# calc5_target_db register map
Vendor: Texas Instruments
Address unit: 16 bits
Registers are 32-bit, read-write, reset 0x0 unless marked. A register's access mark holds for its fields unless they carry their own. Offsets are as the file gives them; [hi:lo] are bit positions; {n}, {i} and the like mark numbered series; 'fields as' and 'values as' point back to an identical list.

## DSS (part 3 of 4) — ipxact12_to_ccs_generated
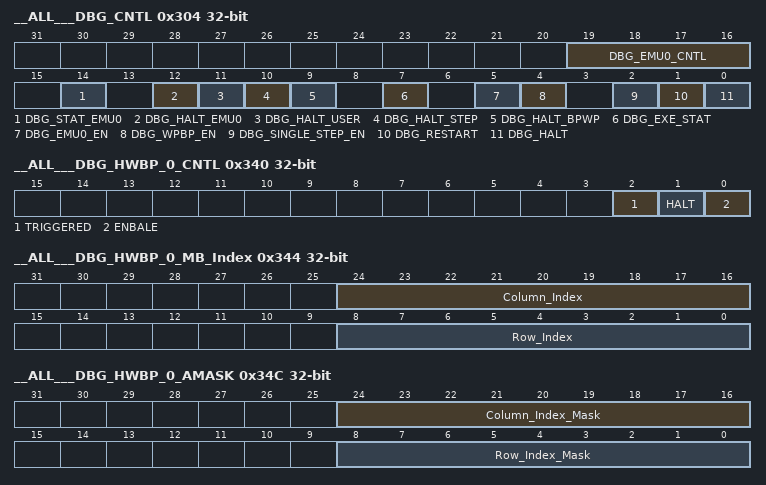
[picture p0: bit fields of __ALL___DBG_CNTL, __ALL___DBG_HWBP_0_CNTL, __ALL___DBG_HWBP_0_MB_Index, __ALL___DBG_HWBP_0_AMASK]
0x304 __ALL___DBG_CNTL access per field — Debug Control register is used by debug software to control all of the basic debug functions.
  [19:16] DBG_EMU0_CNTL ro — EMU0 output control. The cross trigger output control. This values in this field determine the behavior of the outputs generated on EMU0. NOTE: The effect of setting ‘1’ is ignored if the HWA Core is currently in HALTED state until the HWA core exits and re-enters HALTED state. 0 : No output. Input only 1 : Pulse on halt. If this bit is set when halted then no effect until the HWA re-enters halted state. 2 : Pulse when any HWBP triggers 3 : Pulse when any HWWP triggers 4 : Drive pin high 5 : Drive pin low 6-15 : Reserved
  [14] DBG_STAT_EMU0 ro — Statues of EMU0 input. This bit indicates the current value of the EMU0 input
  [12] DBG_HALT_EMU0 ro — Execution halted due to trigger in on EMU0 input • Set to ‘1’ when halt due to EMU0 input completes • Set to ‘0’ when execution resumes
  [11] DBG_HALT_USER ro — Execution halted due to register update of DBG_HALT • Set to ‘1’ when halt due to DBG_HALT update completes • Set to ‘0’ when execution resumes
  [10] DBG_HALT_STEP ro — Execution halted due to single step completion • Set to ‘1’ when the single step completes • Set to ‘0’ when execution resumes
  [9] DBG_HALT_BPWP ro — Execution halted due to trigger from HWBP or WP. • Set to ‘1’ halt due to breakpoint or watchpoint completes • Set to ‘0’ when execution resumes
  [7] DBG_EXE_STAT ro — The execution status of the module • Set to ‘1’ when halted due to debug event • Set to ‘0’ when execution resumes
  [5] DBG_EMU0_EN rw — EMU0 input trigger enable • Writing ‘1’ enables halting on the falling edge of the EMU0 input • Writing ‘0’ disables halts via EMU0 input
  [4] DBG_WPBP_EN rw — This bit enables the halts on watchpoint or hardware breakpoint trigger events. • Writing ‘1’ enables halting on any hardware breakpoint or watchpoint trigger  Each breakpoint or watchpoint resource also has a local enable • Writing ‘0’ disables halts via hardware breakpoints or watchpoints
  [2] DBG_SINGLE_STEP_EN rw — Single Step Execution enable When this bit is set, the accelerator core shall be halted upon execution of a single instruction. This is after the accelerator core has left the halted state by clearing the DBG_HALT control bit. • Writing ‘1’ enables halting when the next instruction following exit from halted state is executed. • Writing ‘0’ disables halts via single step. NOTE: 1. When the accelerator core enters its natural execution state, it may or may not execute an instruction and re-enter HALTED state.
  [1] DBG_RESTART rw — Debug Restart Status bit • Reading ‘1’ means HWA Core exited halted state (at least temporarily). • Reading ‘0’ means HWA Core did not exit halted state. • Writing ‘1’ shall clear the bit if set. There is no restriction on when it can be cleared. • Writing ‘0’ shall have no effect.
  [0] DBG_HALT rw — Global debug run control The bit will be read as being set upon entry to HALTED state due to halted state being entered because of SWBP, HWBP, HWWP, EMU0 / 1 trigger or manual halt requested through this control. • Writing ‘1’ when read ‘0’ shall cause a halt on the next possible halt boundary. • Writing ‘0’ when read ‘1’ returns the system to the natural execution state. • Reading ‘1’ means that the halted state has been reached. • Reading ‘0’ means that the target is in its natural execution state. NOTE: 1. The natural execution state means the FSM state entered prior to last entry into Halted state. 2. This would be the last application requested FSM state unless the DBG_SYS_EXE_REQ control was used to change it.
0x340 __ALL___DBG_HWBP_0_CNTL access per field — Hardware Brakepoint-0 Control (at MB-Index)
  [2] TRIGGERED rw — This bit is Set to "1" when HWBP located at the MB_Index in DBG_HWBP_n_MB_Index is executed Set to ‘1’ when executing the MB index = DBG_HWBP_n_MB_Index Cleared to ‘0’ by writing ‘1’ to this bit
  [1] HALT rw — This bit configures the module to generate halt when triggered [1] : enables a processor halt when triggered. The DBG_CNTL:DBG_HALT_BPWP must also be set for the halt to occur [0] : disables halt upon trigger
  [0] ENBALE rw — This is the local enable for the hardware breakpoint module Writing ‘1’ to this bit enables the module to generate an instruction address match trigger Writing ‘0’ to this bit disables the module
0x344 __ALL___DBG_HWBP_0_MB_Index access per field — Hardware Brakepoint-0 : At MB-Index
  [24:16] Column_Index rw — Column index of the MB. After processing that MB HWA will halt
  [8:0] Row_Index rw — Row index of the MB. After processing that MB HWA will halt
0x34C __ALL___DBG_HWBP_0_AMASK access per field — Hardware Brakepoint-0 : mask At MB-Index
  [24:16] Column_Index_Mask rw — Mask for the column index of DBG_HWBP_n_MB_INDEX
  [8:0] Row_Index_Mask rw — Mask for the row index of DBG_HWBP_n_MB_INDEX
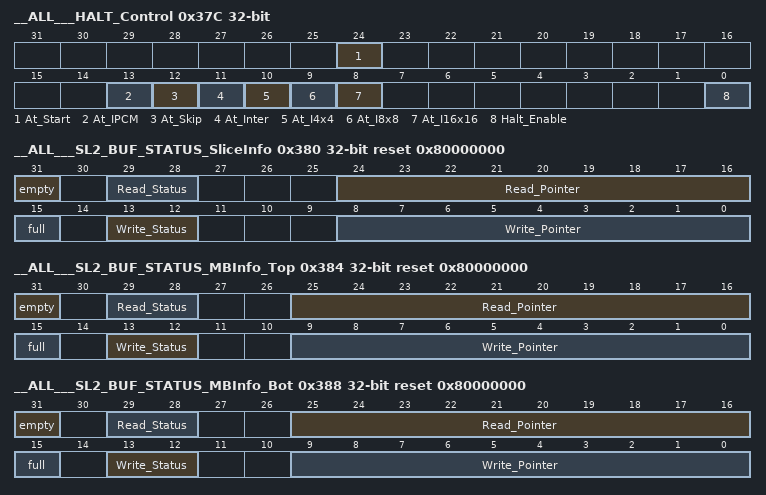
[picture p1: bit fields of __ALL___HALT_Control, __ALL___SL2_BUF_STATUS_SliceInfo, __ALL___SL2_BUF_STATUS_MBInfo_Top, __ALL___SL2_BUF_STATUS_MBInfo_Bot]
0x37C __ALL___HALT_Control access per field — Halt Control of CALC5
  [24] At_Start rw — [1] : Halt when all BC are ready.. (Juster befor start of Computation) [0] : Halt just before releasing BC (Just after computation is done)
  [13] At_IPCM rw — Halt when "mb_type=2" in MB-Info
  [12] At_Skip rw — Halt when MB is skip in MB-Info in Decoder
  [11] At_Inter rw — Halt when "mb_type=3" in MB-Info
  [10] At_I4x4 rw — Halt when "mb_type=0 and tr_8x8=0" in MB-Info
  [9] At_I8x8 rw — Halt when "mb_type=0 and tr_8x8=1" in MB-Info
  [8] At_I16x16 rw — Halt when "mb_type=1" in MB-Info
  [0] Halt_Enable rw — Enable Halt of CALC at different Stage
0x380 __ALL___SL2_BUF_STATUS_SliceInfo ro reset 0x80000000
  [31] empty — buffer empty status ‘1’ -> buffer is empty ‘0’ -> buffer is not empty
  [29:28] Read_Status — Indicates the BC status on the read side BC NOT READY = 00 (rd_core_busy=0 & rd_bc_ready=0) BC READY = 01 (rd_core_busy=0 & rd_bc_ready=1) BC BUSY = 1x (rd_core_busy=1)
  [24:16] Read_Pointer — Current Read pointer value which is going to be read or being read. Read pointer will always be less than equal to ‘Actual buffer depth – 1’
  [15] full — buffer full status ‘1’ -> buffer is full ‘0’ -> buffer is not full
  [13:12] Write_Status — Indicates the BC status on the write side BC NOT READY = 00 (wr_core_busy=0 & wr_bc_ready=0) BC READY = 01 (wr_core_busy=0 & wr_bc_ready=1) BC BUSY = 1x (wr_core_busy=1)
  [8:0] Write_Pointer — Current Write pointer value which is going to be written or which is being written. Write pointer will always be less than equal to ‘Actual buffer depth – 1’
0x384 __ALL___SL2_BUF_STATUS_MBInfo_Top ro reset 0x80000000
  [31] empty — buffer empty status ‘1’ -> buffer is empty ‘0’ -> buffer is not empty
  [29:28] Read_Status — Indicates the BC status on the read side BC NOT READY = 00 (rd_core_busy=0 & rd_bc_ready=0) BC READY = 01 (rd_core_busy=0 & rd_bc_ready=1) BC BUSY = 1x (rd_core_busy=1)
  [25:16] Read_Pointer — Current Read pointer value which is going to be read or being read. Read pointer will always be less than equal to ‘Actual buffer depth – 1’
  [15] full — buffer full status ‘1’ -> buffer is full ‘0’ -> buffer is not full
  [13:12] Write_Status — Indicates the BC status on the write side BC NOT READY = 00 (wr_core_busy=0 & wr_bc_ready=0) BC READY = 01 (wr_core_busy=0 & wr_bc_ready=1) BC BUSY = 1x (wr_core_busy=1)
  [9:0] Write_Pointer — Current Write pointer value which is going to be written or which is being written. Write pointer will always be less than equal to ‘Actual buffer depth – 1’
0x388 __ALL___SL2_BUF_STATUS_MBInfo_Bot ro reset 0x80000000
  fields as __ALL___SL2_BUF_STATUS_MBInfo_Top
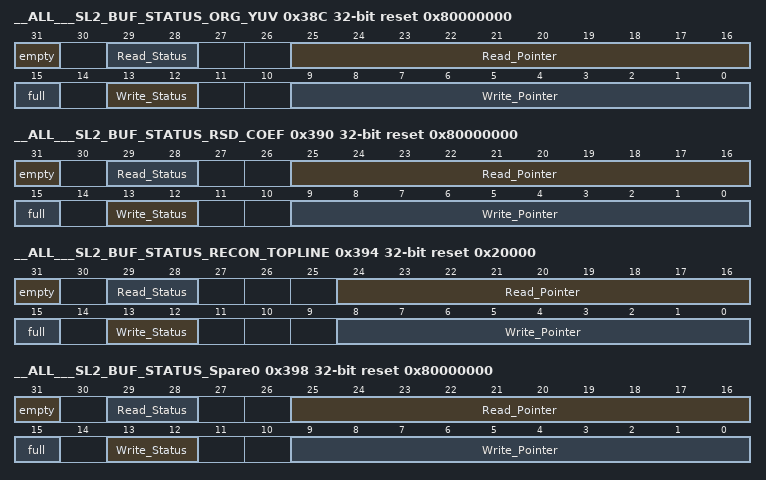
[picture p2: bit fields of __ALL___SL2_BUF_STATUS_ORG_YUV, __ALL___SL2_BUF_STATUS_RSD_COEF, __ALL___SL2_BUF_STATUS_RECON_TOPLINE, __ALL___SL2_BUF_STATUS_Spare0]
0x38C __ALL___SL2_BUF_STATUS_ORG_YUV ro reset 0x80000000
  fields as __ALL___SL2_BUF_STATUS_MBInfo_Top
0x390 __ALL___SL2_BUF_STATUS_RSD_COEF ro reset 0x80000000
  fields as __ALL___SL2_BUF_STATUS_MBInfo_Top
0x394 __ALL___SL2_BUF_STATUS_RECON_TOPLINE ro reset 0x20000
  fields as __ALL___SL2_BUF_STATUS_SliceInfo
0x398 __ALL___SL2_BUF_STATUS_Spare0 ro reset 0x80000000
  fields as __ALL___SL2_BUF_STATUS_MBInfo_Top
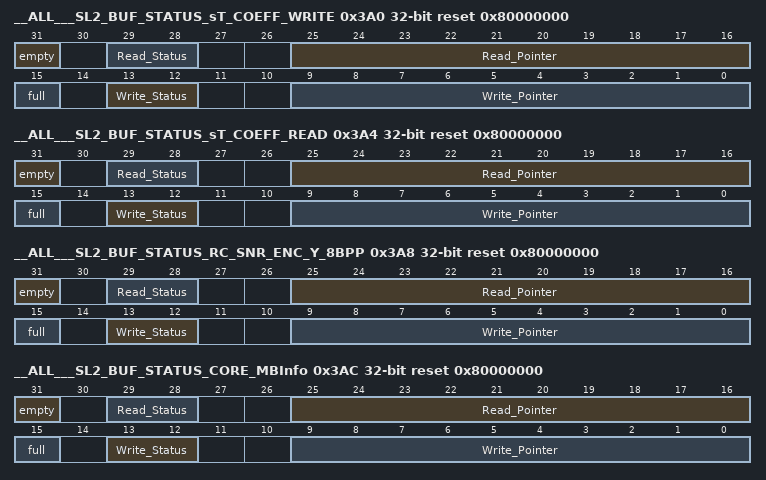
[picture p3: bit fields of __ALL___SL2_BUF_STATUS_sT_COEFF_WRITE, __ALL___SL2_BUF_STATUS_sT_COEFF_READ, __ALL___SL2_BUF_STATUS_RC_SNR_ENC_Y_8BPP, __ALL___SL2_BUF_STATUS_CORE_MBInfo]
0x3A0 __ALL___SL2_BUF_STATUS_sT_COEFF_WRITE ro reset 0x80000000 — stcoeff write SL2BC status
  fields as __ALL___SL2_BUF_STATUS_MBInfo_Top
0x3A4 __ALL___SL2_BUF_STATUS_sT_COEFF_READ ro reset 0x80000000 — stcoeff read SL2BC status
  fields as __ALL___SL2_BUF_STATUS_MBInfo_Top
0x3A8 __ALL___SL2_BUF_STATUS_RC_SNR_ENC_Y_8BPP ro reset 0x80000000 — rc 8bpp luma data write SL2BC status
  fields as __ALL___SL2_BUF_STATUS_MBInfo_Top
0x3AC __ALL___SL2_BUF_STATUS_CORE_MBInfo ro reset 0x80000000 — SL2BC between calc core and drm status
  fields as __ALL___SL2_BUF_STATUS_MBInfo_Top
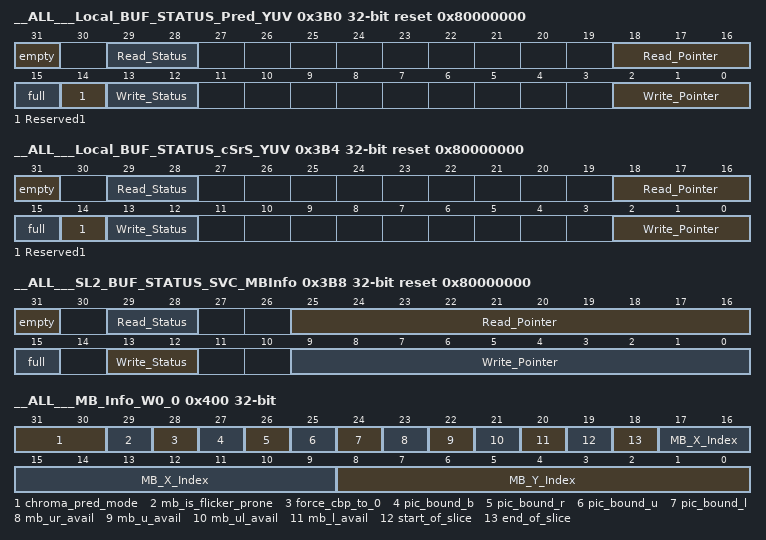
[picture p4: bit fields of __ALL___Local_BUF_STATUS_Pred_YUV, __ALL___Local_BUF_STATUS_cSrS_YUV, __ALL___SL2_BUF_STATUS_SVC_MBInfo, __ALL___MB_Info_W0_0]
0x3B0 __ALL___Local_BUF_STATUS_Pred_YUV ro reset 0x80000000 — Status of Pred-Buffer (LBC)
  [31] empty — buffer empty status ‘1’ -> buffer is empty ‘0’ -> buffer is not empty
  [29:28] Read_Status — Indicates the BC status on the read side BC NOT READY = 00 (rd_core_busy=0 & rd_bc_ready=0) BC READY = 01 (rd_core_busy=0 & rd_bc_ready=1) BC BUSY = 1x (rd_core_busy=1)
  [18:16] Read_Pointer — Current Read pointer value which is going to be read or being read. Read pointer will always be less than equal to ‘Actual buffer depth – 1’
  [15] full — buffer full status ‘1’ -> buffer is full ‘0’ -> buffer is not full
  [14] Reserved1 — Indicates the BC status on the write side BC NOT READY = 00 (wr_core_busy=0 & wr_bc_ready=0) BC READY = 01 (wr_core_busy=0 & wr_bc_ready=1) BC BUSY = 1x (wr_core_busy=1)
  [13:12] Write_Status
  [2:0] Write_Pointer — Current Write pointer value which is going to be written or which is being written. Write pointer will always be less than equal to ‘Actual buffer depth – 1’
0x3B4 __ALL___Local_BUF_STATUS_cSrS_YUV ro reset 0x80000000 — Status of cS/rS-Buffer (LBC) used in SVC
  fields as __ALL___Local_BUF_STATUS_Pred_YUV
0x3B8 __ALL___SL2_BUF_STATUS_SVC_MBInfo ro reset 0x80000000 — SL2BC between me and calc drm status
  fields as __ALL___SL2_BUF_STATUS_MBInfo_Top
0x3C0 __ALL___W_BUF_STATUS_RECON_LEFTLINE ro reset 0x3
  [1:0] ul_refpix_ptr — Upper-Left Reference-Pixel pointer in W-buf
0x400 __ALL___MB_Info_W0_0 ro
  [31:30] chroma_pred_mode — In Intra -> contain Chrom Pred Mode. In Inter -> LSB contain SKIP status
  [29] mb_is_flicker_prone — In Encode valid for I-Frame Only [0] : Normal Function. [1] : Use MC output as Original.
  [28] force_cbp_to_0 — In Encoder [0] -> Normal Operation [1] -> DIFF will be Forced to Zero (Org-Pred = 0) (In Inter it is same as SKIP-MB) In Decoder [0] : Normal MB [1] : MB with Error
  [27] pic_bound_b
  [26] pic_bound_r
  [25] pic_bound_u
  [24] pic_bound_l
  [23] mb_ur_avail
  [22] mb_u_avail
  [21] mb_ul_avail
  [20] mb_l_avail
  [19] start_of_slice
  [18] end_of_slice
  [17:9] MB_X_Index — Column_Index of MB
  [8:0] MB_Y_Index — Row_Index of MB
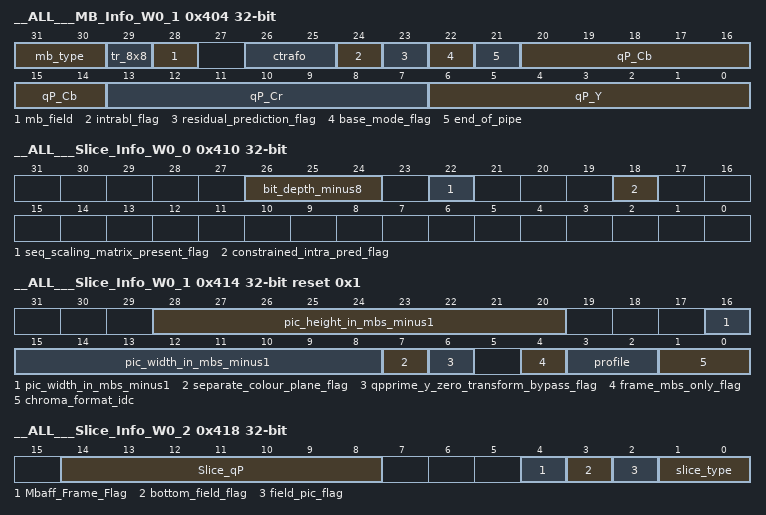
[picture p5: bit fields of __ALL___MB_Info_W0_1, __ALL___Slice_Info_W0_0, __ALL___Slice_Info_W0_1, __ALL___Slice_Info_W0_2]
0x404 __ALL___MB_Info_W0_1 ro
  [31:30] mb_type — [0] : Intra_4x4 or Intra_8x8 [1] : Intra_16x16 [2] : I_PCM [3] : Inter
  [29] tr_8x8 — valid when "mb_type = 0" and "mb_type = 3" [0] : 4x4 transform [1] : 8x8 transform
  [28] mb_field — Valid for MBAFF [0] : Frame MB-pair [1] : Field MB-Pair
  [26:25] ctrafo — SVC field
  [24] intrabl_flag — SVC field
  [23] residual_prediction_flag — SVC field
  [22] base_mode_flag — SVC field
  [21] end_of_pipe
  [20:14] qP_Cb — Cb qP (0-to-39)
  [13:7] qP_Cr — Cr qP (0-to-39)
  [6:0] qP_Y — Luma qP (0-to-51)
0x408 __ALL___MB_Info_W0_2 ro — Intra_mode
  [31:0] Y_pred_mode
0x40C __ALL___MB_Info_W0_3 ro — Intra_Modes
  [31:0] Y_pred_mode
0x410 __ALL___Slice_Info_W0_0 ro
  [26:24] bit_depth_minus8 — specifies the bit depth of the samples of the luma and Chroma (Valid only when design support more than 8-bit pixle)
  [22] seq_scaling_matrix_present_flag — equal to 1 specifies that the WeightScale matrix is present. seq_scaling_matrix_present_flag equal to 0 specifies that these flags are not present and the sequence-level scaling list specified by Flat_4x4_16 (Constant 16 value). This flag can be present only in High-Profile
  [18] constrained_intra_pred_flag
0x414 __ALL___Slice_Info_W0_1 ro reset 0x1
  [28:20] pic_height_in_mbs_minus1
  [16:8] pic_width_in_mbs_minus1
  [7] separate_colour_plane_flag — Valid only for 4:4:4
  [6] qpprime_y_zero_transform_bypass_flag — equal to 1 specifies that, when QP'Y is equal to 0, a transform bypass operation for the transform coefficient decoding process and picture construction process prior to deblocking filter process is applied (Valied only in High 4:4:4 profile)
  [4] frame_mbs_only_flag — equal to 0 specifies that coded pictures of the coded video sequence may either be coded fields or coded frames.
  [3:2] profile — 0: Baseline Profile, 1: Main Profile, 2: High Profile, 3: Reserved.
  [1:0] chroma_format_idc — 0 : 4:0:0, 1 : 4:2:0, 2 : 4:2:2, 3 : 4:4:4
0x418 __ALL___Slice_Info_W0_2 ro
  [14:8] Slice_qP — qP of a slice.
  [4] Mbaff_Frame_Flag — MbaffFrameFlag = ( mb_adaptive_frame_field_flag && !field_pic_flag ). mb_adaptive_frame_field_flag equal to 0 specifies no switching between frame and field macroblock within a picture.
  [3] bottom_field_flag — equal to 1 specifies that the slice is part of a coded bottom field. bottom_field_flag equal to 0 specifies that the picture is a coded top field. When this syntax element is not present for the current slice, it shall be inferred to be equal to 0
  [2] field_pic_flag — equal to 1 specifies that the slice is a slice of a coded field. field_pic_flag equal to 0 specifies that the slice is a slice of a coded frame
  [1:0] slice_type — 0 : I-Slice, 1 : P-Slice, 2 : B-Slie, 3 : Reserved
0x41C __ALL___Slice_Info_W0_3 ro
0x420 __ALL___Core_Status ro
  [0] CORE_Status — CALC5 core status Write [x] : Ignored Read [0] : waiting for Buffer if "CALC5_EN=1" else Idle Read [1] : Computation in progress
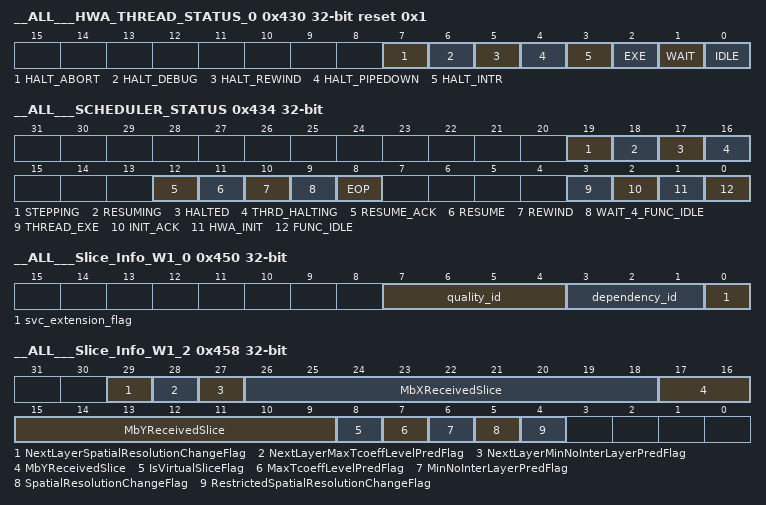
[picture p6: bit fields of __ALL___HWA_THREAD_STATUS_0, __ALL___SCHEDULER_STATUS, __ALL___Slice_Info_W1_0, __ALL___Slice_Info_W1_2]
0x430 __ALL___HWA_THREAD_STATUS_0 ro reset 0x1 — Thread Status
  [7] HALT_ABORT — Halted. abort request is pending
  [6] HALT_DEBUG — Halted. debug request is pending or ongoing.
  [5] HALT_REWIND — Halted because of rewind
  [4] HALT_PIPEDOWN — Thread piped down
  [3] HALT_INTR — Halted because of interrupt request
  [2] EXE — Execution state
  [1] WAIT — Waiting for the Tstart_req
  [0] IDLE — Thread FSM is in IDLE state
0x434 __ALL___SCHEDULER_STATUS ro — Indicates HWA Status
  [19] STEPPING — Stepping the HWA
  [18] RESUMING — Resuming the HWA
  [17] HALTED — HWA halted
  [16] THRD_HALTING — Halting the HWA CORE threads in progress
  [12] RESUME_ACK — = po_resumepipe_ack
  [11] RESUME — HWA is resuming the MB processing. NOTE: po_ rewind_attn = REWIND || RESUME after rewind
  [10] REWIND — HWA is ready to be rewinded
  [9] WAIT_4_FUNC_IDLE — HWA has completed the EOP processing
  [8] EOP — HWA is doing the EOP processing
  [3] THREAD_EXE — HWA Threads are in EXE state
  [2] INIT_ACK — = po_hwa_init_ack
  [1] HWA_INIT — HWA is autoloading/initializing
  [0] FUNC_IDLE — Idle state
{0x440+4i} __ALL___MB_Info_W1_{i} ro (i=0..2)
0x44C __ALL___MB_Info_W1_3 ro
  [22:16] dqId — SVC field
0x450 __ALL___Slice_Info_W1_0 ro
  [7:4] quality_id — Quality/MGS layer id.
  [3:1] dependency_id — Spatial/CGS layer Id.
  [0] svc_extension_flag — svc_extension_flag indicates whether a nal_unit_header_svc_extension( ) or nal_unit_header_mvc_extension( ) is in in the syntax structure. Must be 1 for SVC.
0x454 __ALL___Slice_Info_W1_1 ro
0x458 __ALL___Slice_Info_W1_2 ro
  [29] NextLayerSpatialResolutionChangeFlag — 0: Next layer has same resolution as this layer. 1: Next layer has a different resolution. This flag determines which all inter layer prediction signals to send out from this layer.
  [28] NextLayerMaxTcoeffLevelPredFlag — Is tcoeff_level_prediction_flag equal to 1 for atleast one slice in the next layer. Determines whether transform data (sTCoeff) or quantized levels (tCoeffLevel) will be sent out from this layer to SDRAM. 0: sTCoeff 1: tCoeffLevel. Must be 0 for encoder.
  [27] NextLayerMinNoInterLayerPredFlag — Is no_inter_layer_prediction_flag equal to 0 for atleast one slice for the next layer. Indicates whether inter layer prediction is used by atleast one slice
  [26:18] MbXReceivedSlice — mbXReceivedSlice can be different from mb_x if this is a virtual slice, (i.e. if virtualSliceFlag is 1). Must be 0 in encoder.
  [17:9] MbYReceivedSlice — mbYReceivedSlice can be different from mb_y if this is a virtual slice (i.e. if virtualSliceFlag is 1). Must be 0 in encoder.
  [8] IsVirtualSliceFlag — Is this a slice that was discarded (intentionally) from an SNR enhancement layer (or unintentionally from spatial layer?) If this is 1, slice_skip_flag also must be set and the decoder will decode as though this is a skip slice.
  [7] MaxTcoeffLevelPredFlag — Is tcoeff_level_prediction_flag equal to 1 for atleast one slice in this layer. Must be 0 for encoder.
  [6] MinNoInterLayerPredFlag — Is no_inter_layer_prediction_flag equal to 0 for atleast one slice for this layer. This indicates inter layer prediction is used by atleast one slice in this layer.
  [5] SpatialResolutionChangeFlag — Flag indicating if this is a spatial enhancement layer
  [4] RestrictedSpatialResolutionChangeFlag — Flag indicating if this is 1:1 or 1:2 scalability with restrictions.
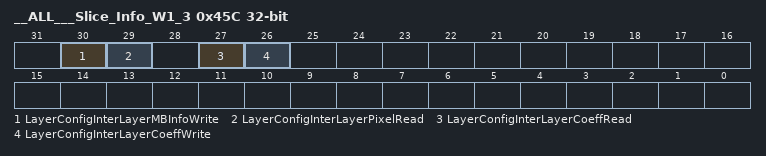
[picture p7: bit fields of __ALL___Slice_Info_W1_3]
0x45C __ALL___Slice_Info_W1_3 ro
  [30] LayerConfigInterLayerMBInfoWrite — Controls CALC vDMA trigger for storing MBInfo to SDRAM.
  [29] LayerConfigInterLayerPixelRead — Controls Pixels scaler vDMA trigger for fetching rS/cS from SDRAM. Also CALC read trigger of rS/cS from SL2 can be avoided if this flag is 0.
  [27] LayerConfigInterLayerCoeffRead — Controls CALC vDMA trigger for fetching sTcoeff/tCoeffLevel from SDRAM
  [26] LayerConfigInterLayerCoeffWrite — Controls CALC vDMA trigger for storing sTcoeff/tCoeffLevel to SDRAM
0x1000 mem__0_one_word
  [31:0] mem_word
0x1004 mem__1_one_word
  [31:0] mem_word
0x1008 mem__2_one_word
  [31:0] mem_word
0x100C mem__3_one_word
  [31:0] mem_word
0x1010 mem__4_one_word
  [31:0] mem_word
0x1014 mem__5_one_word
  [31:0] mem_word
0x1018 mem__6_one_word
  [31:0] mem_word
0x101C mem__7_one_word
  [31:0] mem_word
0x1020 mem__8_one_word
  [31:0] mem_word
0x1024 mem__9_one_word
  [31:0] mem_word
0x1028 mem__10_one_word
  [31:0] mem_word
0x102C mem__11_one_word
  [31:0] mem_word
0x1030 mem__12_one_word
  [31:0] mem_word
0x1034 mem__13_one_word
  [31:0] mem_word
0x1038 mem__14_one_word
  [31:0] mem_word
0x103C mem__15_one_word
  [31:0] mem_word
0x1040 mem__16_one_word
  [31:0] mem_word
0x1044 mem__17_one_word
  [31:0] mem_word
0x1048 mem__18_one_word
  [31:0] mem_word
0x104C mem__19_one_word
  [31:0] mem_word
0x1050 mem__20_one_word
  [31:0] mem_word
0x1054 mem__21_one_word
  [31:0] mem_word
0x1058 mem__22_one_word
  [31:0] mem_word
0x105C mem__23_one_word
  [31:0] mem_word
0x1060 mem__24_one_word
  [31:0] mem_word
0x1064 mem__25_one_word
  [31:0] mem_word
0x1068 mem__26_one_word
  [31:0] mem_word
0x106C mem__27_one_word
  [31:0] mem_word
0x1070 mem__28_one_word
  [31:0] mem_word
0x1074 mem__29_one_word
  [31:0] mem_word
0x1078 mem__30_one_word
  [31:0] mem_word
0x107C mem__31_one_word
  [31:0] mem_word
0x1080 mem__32_one_word
  [31:0] mem_word
0x1084 mem__33_one_word
  [31:0] mem_word
0x1088 mem__34_one_word
  [31:0] mem_word
0x108C mem__35_one_word
  [31:0] mem_word
0x1090 mem__36_one_word
  [31:0] mem_word
0x1094 mem__37_one_word
  [31:0] mem_word
0x1098 mem__38_one_word
  [31:0] mem_word
0x109C mem__39_one_word
  [31:0] mem_word
0x10A0 mem__40_one_word
  [31:0] mem_word
0x10A4 mem__41_one_word
  [31:0] mem_word
0x10A8 mem__42_one_word
  [31:0] mem_word
0x10AC mem__43_one_word
  [31:0] mem_word
0x10B0 mem__44_one_word
  [31:0] mem_word
0x10B4 mem__45_one_word
  [31:0] mem_word
0x10B8 mem__46_one_word
  [31:0] mem_word
0x10BC mem__47_one_word
  [31:0] mem_word
0x10C0 mem__48_one_word
  [31:0] mem_word
0x10C4 mem__49_one_word
  [31:0] mem_word
0x10C8 mem__50_one_word
  [31:0] mem_word
0x10CC mem__51_one_word
  [31:0] mem_word
0x10D0 mem__52_one_word
  [31:0] mem_word
0x10D4 mem__53_one_word
  [31:0] mem_word
0x10D8 mem__54_one_word
  [31:0] mem_word
0x10DC mem__55_one_word
  [31:0] mem_word
0x10E0 mem__56_one_word
  [31:0] mem_word
0x10E4 mem__57_one_word
  [31:0] mem_word
0x10E8 mem__58_one_word
  [31:0] mem_word
0x10EC mem__59_one_word
  [31:0] mem_word
0x10F0 mem__60_one_word
  [31:0] mem_word
0x10F4 mem__61_one_word
  [31:0] mem_word
0x10F8 mem__62_one_word
  [31:0] mem_word
{0x1000+4i} mem__{i}_one_word (i=63..511)
  [31:0] mem_word
0x3000 mem__0_one_word
  [31:0] mem_word
0x3004 mem__1_one_word
  [31:0] mem_word
0x3008 mem__2_one_word
  [31:0] mem_word
0x300C mem__3_one_word
  [31:0] mem_word
0x3010 mem__4_one_word
  [31:0] mem_word
0x3014 mem__5_one_word
  [31:0] mem_word
0x3018 mem__6_one_word
  [31:0] mem_word
0x301C mem__7_one_word
  [31:0] mem_word
0x3020 mem__8_one_word
  [31:0] mem_word
0x3024 mem__9_one_word
  [31:0] mem_word
0x3028 mem__10_one_word
  [31:0] mem_word
0x302C mem__11_one_word
  [31:0] mem_word
0x3030 mem__12_one_word
  [31:0] mem_word
0x3034 mem__13_one_word
  [31:0] mem_word
0x3038 mem__14_one_word
  [31:0] mem_word
0x303C mem__15_one_word
  [31:0] mem_word
0x3040 mem__16_one_word
  [31:0] mem_word
0x3044 mem__17_one_word
  [31:0] mem_word
0x3048 mem__18_one_word
  [31:0] mem_word
0x304C mem__19_one_word
  [31:0] mem_word
0x3050 mem__20_one_word
  [31:0] mem_word
0x3054 mem__21_one_word
  [31:0] mem_word
0x3058 mem__22_one_word
  [31:0] mem_word
0x305C mem__23_one_word
  [31:0] mem_word
0x3060 mem__24_one_word
  [31:0] mem_word
0x3064 mem__25_one_word
  [31:0] mem_word
0x3068 mem__26_one_word
  [31:0] mem_word
0x306C mem__27_one_word
  [31:0] mem_word
0x3070 mem__28_one_word
  [31:0] mem_word
0x3074 mem__29_one_word
  [31:0] mem_word
0x3078 mem__30_one_word
  [31:0] mem_word
0x307C mem__31_one_word
  [31:0] mem_word
0x3080 mem__32_one_word
  [31:0] mem_word
0x3084 mem__33_one_word
  [31:0] mem_word
0x3088 mem__34_one_word
  [31:0] mem_word
0x308C mem__35_one_word
  [31:0] mem_word
0x3090 mem__36_one_word
  [31:0] mem_word
0x3094 mem__37_one_word
  [31:0] mem_word
0x3098 mem__38_one_word
  [31:0] mem_word
0x309C mem__39_one_word
  [31:0] mem_word
0x30A0 mem__40_one_word
  [31:0] mem_word
0x30A4 mem__41_one_word
  [31:0] mem_word
0x30A8 mem__42_one_word
  [31:0] mem_word
0x30AC mem__43_one_word
  [31:0] mem_word
0x30B0 mem__44_one_word
  [31:0] mem_word
0x30B4 mem__45_one_word
  [31:0] mem_word
0x30B8 mem__46_one_word
  [31:0] mem_word
0x30BC mem__47_one_word
  [31:0] mem_word
0x30C0 mem__48_one_word
  [31:0] mem_word
0x30C4 mem__49_one_word
  [31:0] mem_word
0x30C8 mem__50_one_word
  [31:0] mem_word
0x30CC mem__51_one_word
  [31:0] mem_word
0x30D0 mem__52_one_word
  [31:0] mem_word
0x30D4 mem__53_one_word
  [31:0] mem_word
0x30D8 mem__54_one_word
  [31:0] mem_word
0x30DC mem__55_one_word
  [31:0] mem_word
0x30E0 mem__56_one_word
  [31:0] mem_word
0x30E4 mem__57_one_word
  [31:0] mem_word
0x30E8 mem__58_one_word
  [31:0] mem_word
0x30EC mem__59_one_word
  [31:0] mem_word
0x30F0 mem__60_one_word
  [31:0] mem_word
0x30F4 mem__61_one_word
  [31:0] mem_word
0x30F8 mem__62_one_word
  [31:0] mem_word
